# colorlight register map
Vendor: litex
Litex SoC 2024-10-31 19:37:26
Registers are 32-bit, read-write, reset 0x0 unless marked. A register's access mark holds for its fields unless they carry their own. Offsets are from the block's base; lines under a group give offsets from that group; [hi:lo] are bit positions; {n}, {i} and the like mark numbered series; 'fields as' and 'values as' point back to an identical list; <NAME> marks a mode.

## Memory map
0x80200000 ETHMEM size 0x4000
0xF0000000 SPIFLASH_MMAP size 0x14
0xF0000800 SPIFLASH_PHY size 0x4
0xF0001000 CTRL size 0xC
0xF0001800 ETHMAC size 0x50
0xF0002000 ETHPHY size 0x10
0xF0002800 HUB75_PALETTE size 0x4
0xF0003000 HUB75 size 0x84
0xF0003800 IDENTIFIER_MEM size 0x4
0xF0004000 SDRAM size 0x1C
0xF0004800 TIMER0 size 0x20
0xF0005000 UART size 0x20

## Interrupts
0 uart (UART)
1 timer0 (TIMER0)
2 ethmac (ETHMAC)

## Further device data
memoryRegions:
  ROM baseAddress=0x00000000 size=0x00010000
  SRAM baseAddress=0x10000000 size=0x00002000
  SPIFLASH baseAddress=0x80000000 size=0x00200000
  MAIN_RAM baseAddress=0x40000000 size=0x00400000
  MAIN_RAM_UNCACHED baseAddress=0x90000000 size=0x00400000
  ETHMAC baseAddress=0x80200000 size=0x00002000
  ETHMAC_RX baseAddress=0x80200000 size=0x00001000
  ETHMAC_TX baseAddress=0x80201000 size=0x00001000
  CSR baseAddress=0xF0000000 size=0x00010000
constants:
  CONFIG_PLATFORM_NAME value=colorlight_5a_75b
  CONFIG_CLOCK_FREQUENCY value=40000000
  CONFIG_CPU_HAS_INTERRUPT value=None
  CONFIG_CPU_RESET_ADDR value=0
  CONFIG_CPU_TYPE_VEXRISCV value=None
  CONFIG_CPU_VARIANT_MINIMAL value=None
  CONFIG_CPU_FAMILY value=riscv
  CONFIG_CPU_NAME value=vexriscv
  CONFIG_CPU_HUMAN_NAME value=VexRiscv_Min
  CONFIG_CPU_NOP value=nop
  CONFIG_IDENTIFIER value=LiteX SoC on Colorlight 5A-75B 2024-10-31 19:34:39
  FLASH_BOOT_ADDRESS value=2148532224
  SPIFLASH_PAGE_SIZE value=256
  CONFIG_L2_SIZE value=8192
  SDRAM_TEST_DISABLE value=None
  CONFIG_CSR_DATA_WIDTH value=32
  CONFIG_CSR_ALIGNMENT value=32
  CONFIG_BUS_STANDARD value=wishbone
  CONFIG_BUS_DATA_WIDTH value=32
  CONFIG_BUS_ADDRESS_WIDTH value=32
  CONFIG_BUS_BURSTING value=0
  ETHMAC_RX_SLOTS value=2
  ETHMAC_TX_SLOTS value=2
  ETHMAC_SLOT_SIZE value=2048
  CONFIG_CPU_INTERRUPTS value=3
  ETHMAC_INTERRUPT value=2
  TIMER0_INTERRUPT value=1
  UART_INTERRUPT value=0

## SPIFLASH_MMAP
Base 0xF0000000
0x00 MMAP_DUMMY_BITS
  [7:0] mmap_dummy_bits
0x04 MASTER_CS
  [0] master_cs
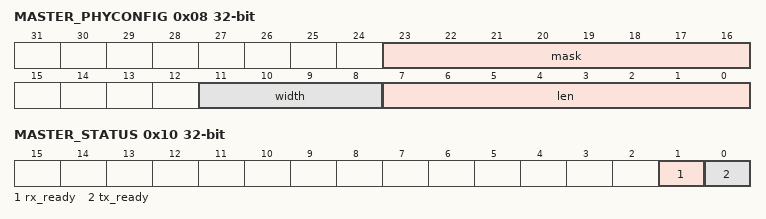
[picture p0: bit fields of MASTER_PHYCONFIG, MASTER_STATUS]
0x08 MASTER_PHYCONFIG — SPI PHY settings.
  [23:16] mask — SPI DQ output enable mask (set bits to ``1`` to enable output drivers on DQ lines).
  [11:8] width — SPI Xfer width (1/2/4/8).
  [7:0] len — SPI Xfer length (in bits).
0x0C MASTER_RXTX
0x10 MASTER_STATUS
  [1] rx_ready — RX FIFO is not empty.
  [0] tx_ready — TX FIFO is not full.

## SPIFLASH_PHY
Base 0xF0000800
0x00 CLK_DIVISOR reset 0x9
  [7:0] clk_divisor

## CTRL
Base 0xF0001000
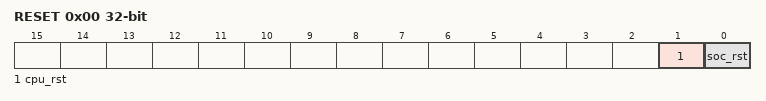
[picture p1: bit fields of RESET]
0x00 RESET
  [1] cpu_rst — Write `1` to this register to reset the CPU(s) of the SoC (Hold Reset)
  [0] soc_rst — Write `1` to this register to reset the full SoC (Pulse Reset)
0x04 SCRATCH reset 0x12345678 — Use this register as a scratch space to verify that software read/write accesses to the Wishbone/CSR bus are working correctly. The initial reset value of 0x1234578 can be used to verify endianness.
0x08 BUS_ERRORS — Total number of Wishbone bus errors (timeouts) since start.

## ETHMAC
Base 0xF0001800
0x00 SRAM_WRITER_SLOT
  [0] sram_writer_slot
0x04 SRAM_WRITER_LENGTH
  [10:0] sram_writer_length
0x08 SRAM_WRITER_ERRORS
0x0C SRAM_WRITER_EV_STATUS — This register contains the current raw level of the available event trigger. Writes to this register have no effect.
  [0] available — Level of the ``available`` event
0x10 SRAM_WRITER_EV_PENDING — When a available event occurs, the corresponding bit will be set in this register. To clear the Event, set the corresponding bit in this register.
  [0] available — `1` if a `available` event occurred. This Event is **level triggered** when the signal is **high**.
0x14 SRAM_WRITER_EV_ENABLE — This register enables the corresponding available events. Write a ``0`` to this register to disable individual events.
  [0] available — Write a ``1`` to enable the ``available`` Event
0x18 SRAM_READER_START
  [0] sram_reader_start
0x1C SRAM_READER_READY
  [0] sram_reader_ready
0x20 SRAM_READER_LEVEL
  [1:0] sram_reader_level
0x24 SRAM_READER_SLOT
  [0] sram_reader_slot
0x28 SRAM_READER_LENGTH
  [10:0] sram_reader_length
0x2C SRAM_READER_EV_STATUS — This register contains the current raw level of the event0 event trigger. Writes to this register have no effect.
  [0] event0 — Level of the ``event0`` event
0x30 SRAM_READER_EV_PENDING — When a event0 event occurs, the corresponding bit will be set in this register. To clear the Event, set the corresponding bit in this register.
  [0] event0 — `1` if a this particular event occurred. This Event is triggered on a **rising** edge.
0x34 SRAM_READER_EV_ENABLE — This register enables the corresponding event0 events. Write a ``0`` to this register to disable individual events.
  [0] event0 — Write a ``1`` to enable the ``event0`` Event
0x38 PREAMBLE_CRC reset 0x1
  [0] preamble_crc
0x3C RX_DATAPATH_PREAMBLE_ERRORS
0x40 RX_DATAPATH_CRC_ERRORS
0x44 IP_ADDRESS reset 0xC0A80132
0x48 MAC_ADDRESS1 reset 0x7648 — Bits 32-47 of `ETHMAC_MAC_ADDRESS`. The value won't take effect until `ETHMAC_MAC_ADDRESS0` is written.
  [31:0] mac_address
0x4C MAC_ADDRESS0 reset 0x74C8C483 — Bits 0-31 of `ETHMAC_MAC_ADDRESS`. Writing this register triggers an update of `ETHMAC_MAC_ADDRESS`.
  [31:0] mac_address
